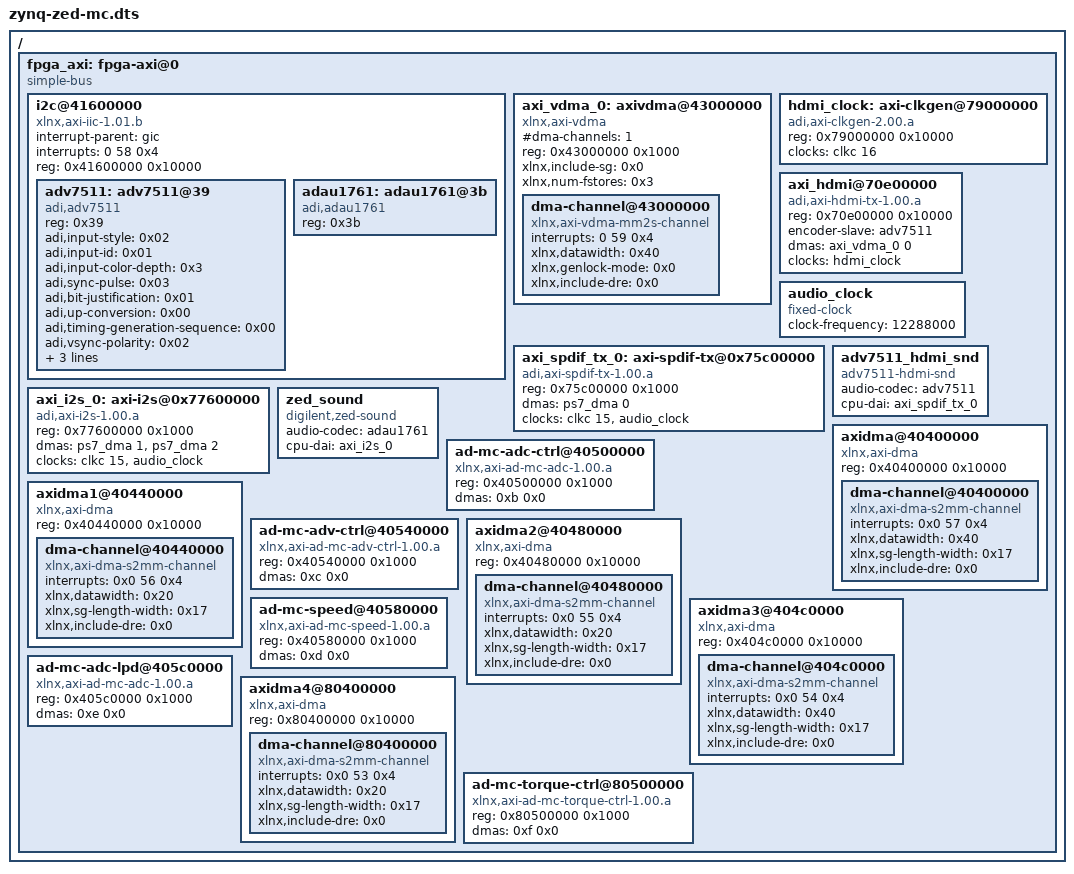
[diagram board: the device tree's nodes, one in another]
/dts-v1/;

/include/ "zynq-zed.dtsi"

/ {
	fpga_axi: fpga-axi@0 {
		compatible = "simple-bus";
		#address-cells = <0x1>;
		#size-cells = <0x1>;
		ranges;

		i2c@41600000 {
			compatible = "xlnx,axi-iic-1.01.b", "xlnx,xps-iic-2.00.a";
			interrupt-parent = <&gic>;
			interrupts = <0 58 0x4>;
			reg = <0x41600000 0x10000>;

			#size-cells = <0>;
			#address-cells = <1>;

			adv7511: adv7511@39 {
				compatible = "adi,adv7511";
				reg = <0x39>;

				adi,input-style = <0x02>;
				adi,input-id = <0x01>;
				adi,input-color-depth = <0x3>;
				adi,sync-pulse = <0x03>;
				adi,bit-justification = <0x01>;
				adi,up-conversion = <0x00>;
				adi,timing-generation-sequence = <0x00>;
				adi,vsync-polarity = <0x02>;
				adi,hsync-polarity = <0x02>;
				adi,tdms-clock-inversion;
				adi,clock-delay = <0x03>;
			};
			
			adau1761: adau1761@3b {
                                compatible = "adi,adau1761";
                                reg = <0x3b>;
                        };

		};

		axi_vdma_0: axivdma@43000000 {
			compatible = "xlnx,axi-vdma";
			#address-cells = <1>;
			#size-cells = <1>;
			#dma-cells = <1>;
			#dma-channels = <1>;
			reg = <0x43000000 0x1000>;
			xlnx,include-sg = <0x0>;
			xlnx,num-fstores = <0x3>;
			dma-channel@43000000 {
				compatible = "xlnx,axi-vdma-mm2s-channel";
				interrupts = <0 59 0x4>;
				xlnx,datawidth = <0x40>;
				xlnx,genlock-mode = <0x0>;
				xlnx,include-dre = <0x0>;
			};
		};

		hdmi_clock: axi-clkgen@79000000 {
			compatible = "adi,axi-clkgen-2.00.a";
			reg = <0x79000000 0x10000>;
			#clock-cells = <0>;
			clocks = <&clkc 16>;
		};

		axi_hdmi@70e00000 {
			compatible = "adi,axi-hdmi-tx-1.00.a";
			reg = <0x70e00000 0x10000>;
			encoder-slave = <&adv7511>;
			dmas = <&axi_vdma_0 0>;
			dma-names = "video";
			clocks = <&hdmi_clock>;
		};


 		audio_clock: audio_clock {
                        compatible = "fixed-clock";
                        #clock-cells = <0>;
                        clock-frequency = <12288000>;
                };

                axi_spdif_tx_0: axi-spdif-tx@0x75c00000 {
                        compatible = "adi,axi-spdif-tx-1.00.a";
                        reg = <0x75c00000 0x1000>;
                        dmas = <&ps7_dma 0>;
                        dma-names = "tx";
                        clocks = <&clkc 15 &audio_clock>;
                        clock-names = "axi", "spdif";
                };

                adv7511_hdmi_snd: adv7511_hdmi_snd {
                        compatible = "adv7511-hdmi-snd";
                        audio-codec = <&adv7511>;
                        cpu-dai = <&axi_spdif_tx_0>;
                };

                axi_i2s_0: axi-i2s@0x77600000 {
                        compatible = "adi,axi-i2s-1.00.a";
                        reg = <0x77600000 0x1000>;
                        dmas = <&ps7_dma 1 &ps7_dma 2>;
                        dma-names = "tx", "rx";
                        clocks = <&clkc 15 &audio_clock>;
                        clock-names = "axi", "i2s";
                };

                zed_sound {
                        compatible = "digilent,zed-sound";
                        audio-codec = <&adau1761>;
                        cpu-dai = <&axi_i2s_0>;
                };

		axidma@40400000 {
			#address-cells = <0x1>;
			#size-cells = <0x1>;
			#dma-cells = <0x1>;
			compatible = "xlnx,axi-dma";
			reg = <0x40400000 0x10000>;
			linux,phandle = <0xb>;
			phandle = <0xb>;

			dma-channel@40400000 {
				compatible = "xlnx,axi-dma-s2mm-channel";
				interrupts = <0x0 57 0x4>;
				xlnx,datawidth = <0x40>;
				xlnx,sg-length-width = <0x17>;
				xlnx,include-dre = <0x0>;
			};
		};

		ad-mc-adc-ctrl@40500000 {
			compatible = "xlnx,axi-ad-mc-adc-1.00.a";
			reg = <0x40500000 0x1000>;
			dmas = <0xb 0x0>;
			dma-names = "ad-mc-adc-dma";
		};

		axidma1@40440000 {
			#address-cells = <0x1>;
			#size-cells = <0x1>;
			#dma-cells = <0x1>;
			compatible = "xlnx,axi-dma";
			reg = <0x40440000 0x10000>;
			linux,phandle = <0xc>;
			phandle = <0xc>;

			dma-channel@40440000 {
				compatible = "xlnx,axi-dma-s2mm-channel";
				interrupts = <0x0 56 0x4>;
				xlnx,datawidth = <0x20>;
				xlnx,sg-length-width = <0x17>;
				xlnx,include-dre = <0x0>;
			};
		};

		ad-mc-adv-ctrl@40540000 {
			compatible = "xlnx,axi-ad-mc-adv-ctrl-1.00.a";
			reg = <0x40540000 0x1000>;
			dmas = <0xc 0x0>;
			dma-names = "ad-mc-adv-ctrl-dma";
		};

		axidma2@40480000 {
			#address-cells = <0x1>;
			#size-cells = <0x1>;
			#dma-cells = <0x1>;
			compatible = "xlnx,axi-dma";
			reg = <0x40480000 0x10000>;
			linux,phandle = <0xd>;
			phandle = <0xd>;

			dma-channel@40480000 {
				compatible = "xlnx,axi-dma-s2mm-channel";
				interrupts = <0x0 55 0x4>;
				xlnx,datawidth = <0x20>;
				xlnx,sg-length-width = <0x17>;
				xlnx,include-dre = <0x0>;
			};
		};

		ad-mc-speed@40580000 {
			compatible = "xlnx,axi-ad-mc-speed-1.00.a";
			reg = <0x40580000 0x1000>;
			dmas = <0xd 0x0>;
			dma-names = "ad-mc-speed-dma";
		};

		axidma3@404c0000 {
			#address-cells = <0x1>;
			#size-cells = <0x1>;
			#dma-cells = <0x1>;
			compatible = "xlnx,axi-dma";
			reg = <0x404c0000 0x10000>;
			linux,phandle = <0xe>;
			phandle = <0xe>;

			dma-channel@404c0000 {
				compatible = "xlnx,axi-dma-s2mm-channel";
				interrupts = <0x0 54 0x4>;
				xlnx,datawidth = <0x40>;
				xlnx,sg-length-width = <0x17>;
				xlnx,include-dre = <0x0>;
			};
		};

		ad-mc-adc-lpd@405c0000 {
			compatible = "xlnx,axi-ad-mc-adc-1.00.a";
			reg = <0x405c0000 0x1000>;
			dmas = <0xe 0x0>;
			dma-names = "ad-mc-adc-dma";
		};

		axidma4@80400000 {
			#address-cells = <0x1>;
			#size-cells = <0x1>;
			#dma-cells = <0x1>;
			compatible = "xlnx,axi-dma";
			reg = <0x80400000 0x10000>;
			linux,phandle = <0xf>;
			phandle = <0xf>;

			dma-channel@80400000 {
				compatible = "xlnx,axi-dma-s2mm-channel";
				interrupts = <0x0 53 0x4>;
				xlnx,datawidth = <0x20>;
				xlnx,sg-length-width = <0x17>;
				xlnx,include-dre = <0x0>;
			};
		};

		ad-mc-torque-ctrl@80500000 {
			compatible = "xlnx,axi-ad-mc-torque-ctrl-1.00.a";
			reg = <0x80500000 0x1000>;
			dmas = <0xf 0x0>;
			dma-names = "ad-mc-torque-ctrl-dma";
		};

	};

};
